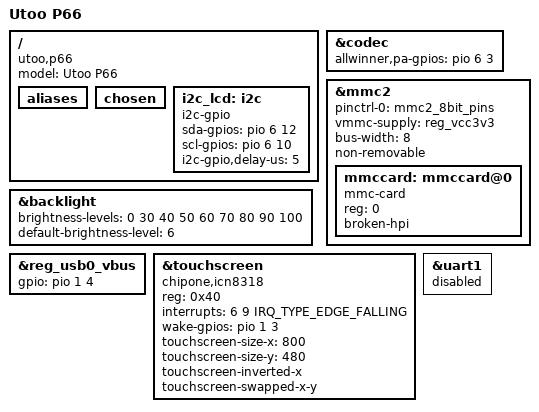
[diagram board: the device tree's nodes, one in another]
/dts-v1/;
#include "sun5i-a13.dtsi"
#include "sun5i-reference-design-tablet.dtsi"
#include <dt-bindings/interrupt-controller/irq.h>
/ {
	model = "Utoo P66";
	compatible = "utoo,p66", "allwinner,sun5i-a13";
	aliases {
		/delete-property/serial0;
	};
	chosen {
		/delete-property/stdout-path;
	};
	i2c_lcd: i2c {
		compatible = "i2c-gpio";
		sda-gpios = <&pio 6 12 (GPIO_ACTIVE_HIGH | GPIO_PULL_UP)>;  
		scl-gpios = <&pio 6 10 (GPIO_ACTIVE_HIGH | GPIO_PULL_UP)>;  
		i2c-gpio,delay-us = <5>;
	};
};
&backlight {
	brightness-levels = <0 30 40 50 60 70 80 90 100>;
	default-brightness-level = <6>;
};
&codec {
	allwinner,pa-gpios = <&pio 6 3 GPIO_ACTIVE_HIGH>;  
};
&mmc2 {
	pinctrl-names = "default";
	pinctrl-0 = <&mmc2_8bit_pins>;
	vmmc-supply = <&reg_vcc3v3>;
	bus-width = <8>;
	non-removable;
	status = "okay";
	mmccard: mmccard@0 {
		reg = <0>;
		compatible = "mmc-card";
		broken-hpi;
	};
};
&reg_usb0_vbus {
	gpio = <&pio 1 4 GPIO_ACTIVE_HIGH>;  
};
&touchscreen {
	compatible = "chipone,icn8318";
	reg = <0x40>;
	interrupts = <6 9 IRQ_TYPE_EDGE_FALLING>;  
	wake-gpios = <&pio 1 3 GPIO_ACTIVE_HIGH>;  
	touchscreen-size-x = <800>;
	touchscreen-size-y = <480>;
	touchscreen-inverted-x;
	touchscreen-swapped-x-y;
	status = "okay";
};
&uart1 {
	status = "disabled";
};
